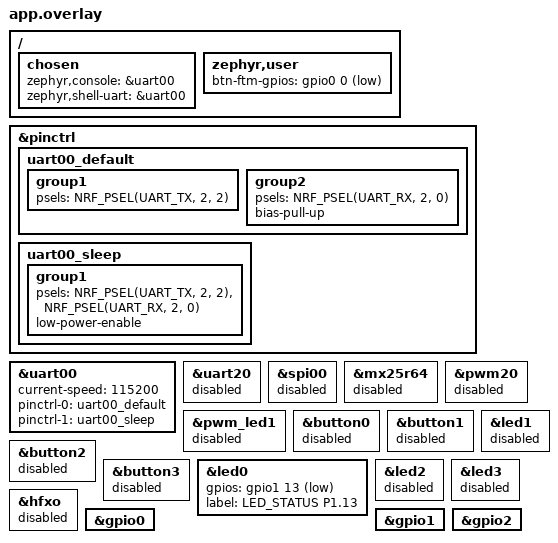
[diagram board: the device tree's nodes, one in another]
/*
 * demo — 临时适配 ink_panel EVT 冒烟（原 TY rev_a：UART P1.04/05 LED P2.08/09）
 *
 * UART00 console: TX=P2.02  RX=P2.00  @ 115200
 * LED0=P1.13 ACTIVE_LOW（LED_STATUS_N）；单灯
 * FTM 按键：P0.00
 * 时钟：LF=RC；HFXO 关（EVT 晶振未起时 start 会死等无灯）
 */

#include <zephyr/dt-bindings/gpio/gpio.h>
#include <zephyr/dt-bindings/pinctrl/nrf-pinctrl.h>

&pinctrl {
	uart00_default: uart00_default {
		group1 {
			psels = <NRF_PSEL(UART_TX, 2, 2)>;
		};
		group2 {
			psels = <NRF_PSEL(UART_RX, 2, 0)>;
			bias-pull-up;
		};
	};

	uart00_sleep: uart00_sleep {
		group1 {
			psels = <NRF_PSEL(UART_TX, 2, 2)>,
				<NRF_PSEL(UART_RX, 2, 0)>;
			low-power-enable;
		};
	};
};

&uart00 {
	status = "okay";
	current-speed = <115200>;
	pinctrl-0 = <&uart00_default>;
	pinctrl-1 = <&uart00_sleep>;
	pinctrl-names = "default", "sleep";
};

&uart20 {
	status = "disabled";
};

/* SERIAL00 与 uart00 互斥：关掉 DK SPI NOR */
&spi00 {
	status = "disabled";
};

&mx25r64 {
	status = "disabled";
};

/* DK 默认外设关掉，避免占脚 */
&pwm20 {
	status = "disabled";
};

&pwm_led1 {
	status = "disabled";
};

/* DK button0 与 EVT LED 同脚 P1.13，必须关掉 */
&button0 {
	status = "disabled";
};

&button1 {
	status = "disabled";
};

&button2 {
	status = "disabled";
};

&button3 {
	status = "disabled";
};

&led0 {
	gpios = <&gpio1 13 GPIO_ACTIVE_LOW>;
	label = "LED_STATUS P1.13";
};

&led1 {
	status = "disabled";
};

&led2 {
	status = "disabled";
};

&led3 {
	status = "disabled";
};

/* EVT 冒烟：不启外部晶振，避免 hfxo_start 死等 */
&hfxo {
	status = "disabled";
};

&gpio0 {
	status = "okay";
};

&gpio1 {
	status = "okay";
};

&gpio2 {
	status = "okay";
};

/ {
	chosen {
		zephyr,console = &uart00;
		zephyr,shell-uart = &uart00;
	};

	zephyr,user {
		btn-ftm-gpios = <&gpio0 0 (GPIO_ACTIVE_LOW | GPIO_PULL_UP)>;
	};
};
